# STM32MP25_CM33 register map
File version: 1.3
CPU: CM33 r0p1, little endian, MPU, FPU, vendor SysTick, 8 interrupt priority bits
Registers are 32-bit, read-write, reset 0x0 unless marked. A register's access mark holds for its fields unless they carry their own. Offsets are from the block's base; [hi:lo] are bit positions; {n}, {i} and the like mark numbered series.

## DDRDBG — DDRDBG address block description
Base 0x48050000
Same registers: DDRDBG_S 0x58050000
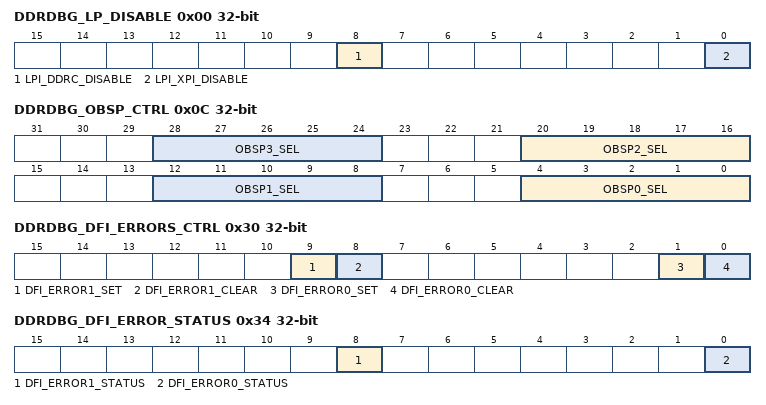
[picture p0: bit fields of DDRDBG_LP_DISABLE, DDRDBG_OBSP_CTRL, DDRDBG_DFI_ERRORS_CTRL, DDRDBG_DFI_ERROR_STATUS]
0x00 DDRDBG_LP_DISABLE — DDRDBG low-power disable register
  [8] LPI_DDRC_DISABLE
    0=No effect; 1=Disable automatic clock gating of DDRC when idle
  [0] LPI_XPI_DISABLE
    0=No effect; 1=Disable automatic clock gating of XPIs when idle
0x04 DDRDBG_BYPASS_PCLKEN
  [0] ENABLE
    0=No effect; 1=The DDRPHYC Bypass_Pclken is active. The targeted data rate is less than 666 MT/s. The clock fed to the SDRAM interface is the one coming directly from the interfan frac pll, and the DDRPHYC does not alter it.
0x08 DDRDBG_DDRC_AUTO_SR_DELAY reset 0x20
  [7:0] DELAY_CYCLES — Number of delay cycles to wait before to gate down the DDRC clock when in auto self-refresh This delay allows any ongoing register access to be completed before gating the DDRC clock.
0x0C DDRDBG_OBSP_CTRL — DDRDBG OBSP control register
  [8n+4:8n] OBSP{n}_SEL (n=0..3) — Selects which of the input observable signal is forwarded to the HDP on selectable observability line {n}.
0x10 DDRDBG_FRAC_PLL_LOCK
  [0] LOCK
    0=No effect; 1=PLL lock, direct copy of ddrss_pll2_lock
0x14 DDRDBG_DTO_OUTPUT
  [0] DTO — the DDRPHYC PLL lock can be observed in this register.
    0=No effect; 1=DDRPHYC DTO output is stored in this register. Among other signals of interests,
0x30 DDRDBG_DFI_ERRORS_CTRL — DDRDBG DFI error control register
  [9] DFI_ERROR1_SET
    0=No effect; 1=Trigger the interrupt linked with dfi_error
  [8] DFI_ERROR1_CLEAR
    0=No effect; 1=Clear the interrupt linked with dfi_error1
  [1] DFI_ERROR0_SET
    0=No effect; 1=Trigger the interrupt linked with dfi_error0
  [0] DFI_ERROR0_CLEAR
    0=No effect; 1=Clear the interrupt linked with dfi_error0
0x34 DDRDBG_DFI_ERROR_STATUS
  [8] DFI_ERROR1_STATUS — Status bit for dfi_error1
    0=No effect; 1=Clear the interrupt linked with dfi_error1
  [0] DFI_ERROR0_STATUS — Status bit for dfi_error0
    0=No effect; 1=Clear the interrupt linked with dfi_error0
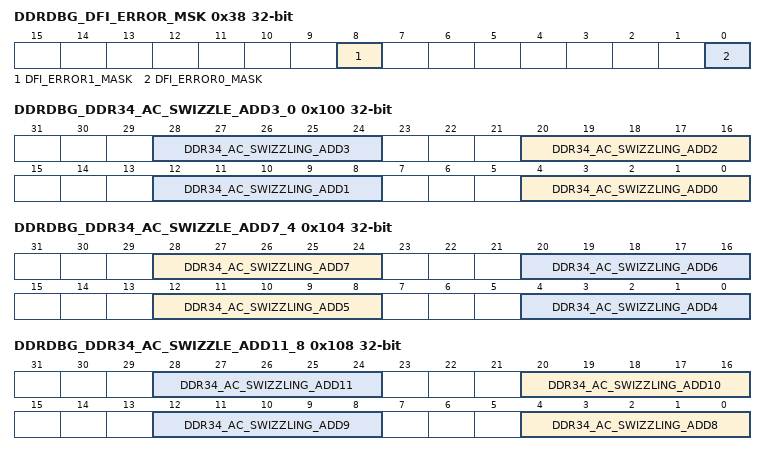
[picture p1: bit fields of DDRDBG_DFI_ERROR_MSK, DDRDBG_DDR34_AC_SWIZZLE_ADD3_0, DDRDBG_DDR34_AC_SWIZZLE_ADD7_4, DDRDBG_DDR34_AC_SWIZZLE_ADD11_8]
0x38 DDRDBG_DFI_ERROR_MSK — DDRDBG DFI error mask register
  [8] DFI_ERROR1_MASK
    0=No effect; 1=Interrupt linked to dfi_error1 is masked. Clear the interrupt linked with dfi_error1.
  [0] DFI_ERROR0_MASK
    0=No effect; 1=Interrupt linked to dfi_error0 is masked. Clear the interrupt linked with dfi_error0.
0x100 DDRDBG_DDR34_AC_SWIZZLE_ADD3_0
  [8n+4:8n] DDR34_AC_SWIZZLING_ADD{n} (n=0..3) — Remapping input bit on add{n} DDRPHYC input at the DFI interface (remapping defined in Table63)
0x104 DDRDBG_DDR34_AC_SWIZZLE_ADD7_4
  [28:24] DDR34_AC_SWIZZLING_ADD7 — Remapping input bit on add7 DDRPHYC input at the DFI interface (remapping is defined in Table63)
  [20:16] DDR34_AC_SWIZZLING_ADD6 — Remapping input bit on add6 DDRPHYC input at the DFI interface (remapping defined in Table63)
  [12:8] DDR34_AC_SWIZZLING_ADD5 — Remapping input bit on add5 DDRPHYC input at the DFI interface (remapping defined in Table63)
  [4:0] DDR34_AC_SWIZZLING_ADD4 — Remapping input bit on add4 DDRPHYC input at the DFI interface (remapping defined in Table63)
0x108 DDRDBG_DDR34_AC_SWIZZLE_ADD11_8
  [8n-60:8n-64] DDR34_AC_SWIZZLING_ADD{n} (n=8..11) — Remapping input bit on add{n} DDRPHYC input at the DFI interface (remapping defined in Table63)
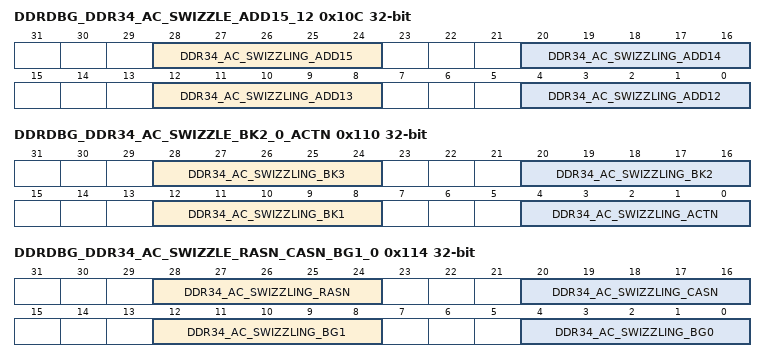
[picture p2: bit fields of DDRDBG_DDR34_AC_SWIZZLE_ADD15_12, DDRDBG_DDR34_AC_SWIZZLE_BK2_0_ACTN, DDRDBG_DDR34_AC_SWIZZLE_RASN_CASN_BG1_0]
0x10C DDRDBG_DDR34_AC_SWIZZLE_ADD15_12
  [28:24] DDR34_AC_SWIZZLING_ADD15 — Remapping input bit on add15 DDRPHYC input at he DFI interface (remapping defined in Table63)
  [20:16] DDR34_AC_SWIZZLING_ADD14 — Remapping input bit on add14 DDRPHYC input at the DFI interface (remapping defined in Table63)
  [12:8] DDR34_AC_SWIZZLING_ADD13 — Remapping input bit on add13 DDRPHYC input at he DFI interface (remapping defined in Table63)
  [4:0] DDR34_AC_SWIZZLING_ADD12 — Remapping input bit on add12 DDRPHYC input at the DFI interface (remapping defined in Table63)
0x110 DDRDBG_DDR34_AC_SWIZZLE_BK2_0_ACTN
  [28:24] DDR34_AC_SWIZZLING_BK3 — Remapping input bit on bk3 DDRPHYC input at the DFI interface (remapping defined in Table63)
  [20:16] DDR34_AC_SWIZZLING_BK2 — Remapping input bit on bk2 DDRPHYC input at the DFI interface (remapping defined in Table63)
  [12:8] DDR34_AC_SWIZZLING_BK1 — Remapping input bit on bk1 DDRPHYC input at the DFI interface (remapping defined in Table63)
  [4:0] DDR34_AC_SWIZZLING_ACTN — Remapping input bit on actn DDRPHYC input at the DFI interface (remapping defined in Table63)
0x114 DDRDBG_DDR34_AC_SWIZZLE_RASN_CASN_BG1_0
  [28:24] DDR34_AC_SWIZZLING_RASN — Remapping input bit on rasn DDRPHYC input at the DFI interface (remapping defined in Table63)
  [20:16] DDR34_AC_SWIZZLING_CASN — Remapping input bit on casn DDRPHYC input at the DFI interface (remapping defined in Table63
  [12:8] DDR34_AC_SWIZZLING_BG1 — Remapping input bit on bg1 DDRPHYC input at the DFI interface (remapping defined in Table63
  [4:0] DDR34_AC_SWIZZLING_BG0 — Remapping input bit on bg0 DDRPHYC input at the DFI interface (remapping defined in Table63
0x118 DDRDBG_DDR34_AC_SWIZZLE_WEN
  [4:0] DDR34_AC_SWIZZLING_WEN — Remapping input bit on wen DDRPHYC input at the DFI interface (remapping defined in Table63
